# USB_USB2SS_PHY2_0F908000h register map
Vendor: Texas Instruments
Registers are 32-bit, read-write, reset 0x0 unless marked. A register's access mark holds for its fields unless they carry their own. Offsets are as the file gives them; [hi:lo] are bit positions; {n}, {i} and the like mark numbered series.

## usb2ss_phy2 (part 3 of 3)
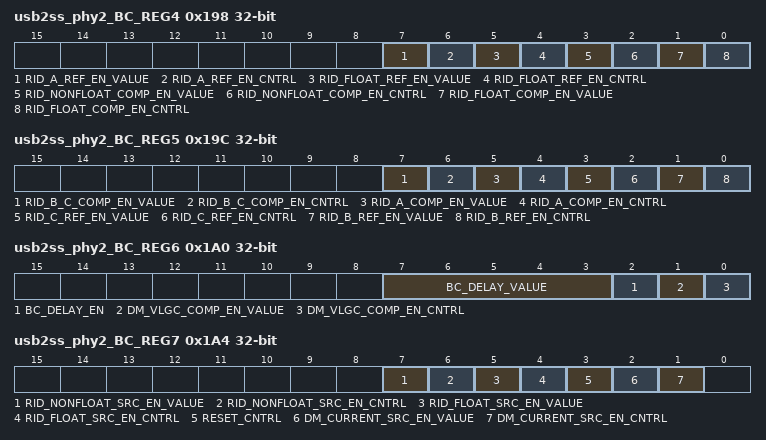
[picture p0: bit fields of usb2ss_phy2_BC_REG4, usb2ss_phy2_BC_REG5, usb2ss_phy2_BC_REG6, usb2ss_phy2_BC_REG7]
0x198 usb2ss_phy2_BC_REG4 — This is a reserved register or field. It should not be written or read, and the value should be ignored.
  [7] RID_A_REF_EN_VALUE — This is a reserved register or field. It should not be written or read, and the value should be ignored. Reset Source: usb2_sync_preset_n
  [6] RID_A_REF_EN_CNTRL — This is a reserved register or field. It should not be written or read, and the value should be ignored. Reset Source: usb2_sync_preset_n
  [5] RID_FLOAT_REF_EN_VALUE — This is a reserved register or field. It should not be written or read, and the value should be ignored. Reset Source: usb2_sync_preset_n
  [4] RID_FLOAT_REF_EN_CNTRL — This is a reserved register or field. It should not be written or read, and the value should be ignored. Reset Source: usb2_sync_preset_n
  [3] RID_NONFLOAT_COMP_EN_VALUE — This is a reserved register or field. It should not be written or read, and the value should be ignored. Reset Source: usb2_sync_preset_n
  [2] RID_NONFLOAT_COMP_EN_CNTRL — This is a reserved register or field. It should not be written or read, and the value should be ignored. Reset Source: usb2_sync_preset_n
  [1] RID_FLOAT_COMP_EN_VALUE — This is a reserved register or field. It should not be written or read, and the value should be ignored. Reset Source: usb2_sync_preset_n
  [0] RID_FLOAT_COMP_EN_CNTRL — This is a reserved register or field. It should not be written or read, and the value should be ignored. Reset Source: usb2_sync_preset_n
0x19C usb2ss_phy2_BC_REG5 — This is a reserved register or field. It should not be written or read, and the value should be ignored.
  [7] RID_B_C_COMP_EN_VALUE — This is a reserved register or field. It should not be written or read, and the value should be ignored. Reset Source: usb2_sync_preset_n
  [6] RID_B_C_COMP_EN_CNTRL — This is a reserved register or field. It should not be written or read, and the value should be ignored. Reset Source: usb2_sync_preset_n
  [5] RID_A_COMP_EN_VALUE — This is a reserved register or field. It should not be written or read, and the value should be ignored. Reset Source: usb2_sync_preset_n
  [4] RID_A_COMP_EN_CNTRL — This is a reserved register or field. It should not be written or read, and the value should be ignored. Reset Source: usb2_sync_preset_n
  [3] RID_C_REF_EN_VALUE — This is a reserved register or field. It should not be written or read, and the value should be ignored. Reset Source: usb2_sync_preset_n
  [2] RID_C_REF_EN_CNTRL — This is a reserved register or field. It should not be written or read, and the value should be ignored. Reset Source: usb2_sync_preset_n
  [1] RID_B_REF_EN_VALUE — This is a reserved register or field. It should not be written or read, and the value should be ignored. Reset Source: usb2_sync_preset_n
  [0] RID_B_REF_EN_CNTRL — This is a reserved register or field. It should not be written or read, and the value should be ignored. Reset Source: usb2_sync_preset_n
0x1A0 usb2ss_phy2_BC_REG6 — This is a reserved register or field. It should not be written or read, and the value should be ignored.
  [7:3] BC_DELAY_VALUE — This is a reserved register or field. It should not be written or read, and the value should be ignored. Reset Source: usb2_sync_preset_n
  [2] BC_DELAY_EN — This is a reserved register or field. It should not be written or read, and the value should be ignored. Reset Source: usb2_sync_preset_n
  [1] DM_VLGC_COMP_EN_VALUE — This is a reserved register or field. It should not be written or read, and the value should be ignored. Reset Source: usb2_sync_preset_n
  [0] DM_VLGC_COMP_EN_CNTRL — This is a reserved register or field. It should not be written or read, and the value should be ignored. Reset Source: usb2_sync_preset_n
0x1A4 usb2ss_phy2_BC_REG7 — This is a reserved register or field. It should not be written or read, and the value should be ignored.
  [7] RID_NONFLOAT_SRC_EN_VALUE — This is a reserved register or field. It should not be written or read, and the value should be ignored. Reset Source: usb2_sync_preset_n
  [6] RID_NONFLOAT_SRC_EN_CNTRL — This is a reserved register or field. It should not be written or read, and the value should be ignored. Reset Source: usb2_sync_preset_n
  [5] RID_FLOAT_SRC_EN_VALUE — This is a reserved register or field. It should not be written or read, and the value should be ignored. Reset Source: usb2_sync_preset_n
  [4] RID_FLOAT_SRC_EN_CNTRL — This is a reserved register or field. It should not be written or read, and the value should be ignored. Reset Source: usb2_sync_preset_n
  [3] RESET_CNTRL — This is a reserved register or field. It should not be written or read, and the value should be ignored. Reset Source: usb2_sync_preset_n
  [2] DM_CURRENT_SRC_EN_VALUE — This is a reserved register or field. It should not be written or read, and the value should be ignored. Reset Source: usb2_sync_preset_n
  [1] DM_CURRENT_SRC_EN_CNTRL — This is a reserved register or field. It should not be written or read, and the value should be ignored. Reset Source: usb2_sync_preset_n
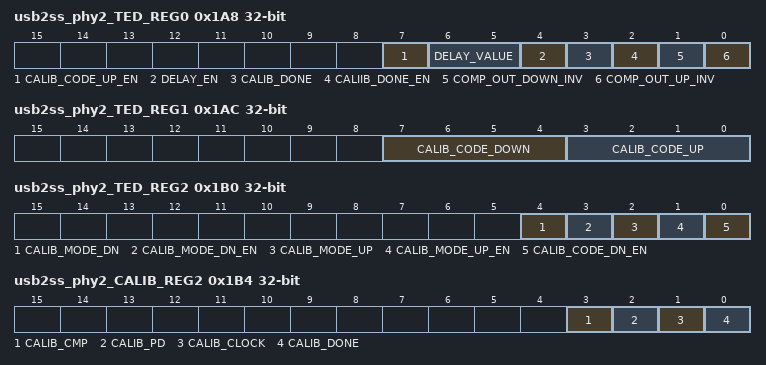
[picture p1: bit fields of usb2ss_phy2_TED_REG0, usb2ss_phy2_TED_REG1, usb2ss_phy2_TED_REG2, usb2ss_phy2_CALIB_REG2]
0x1A8 usb2ss_phy2_TED_REG0 — This is a reserved register or field. It should not be written or read, and the value should be ignored.
  [7] CALIB_CODE_UP_EN — This is a reserved register or field. It should not be written or read, and the value should be ignored. Reset Source: usb2_sync_preset_n
  [6:5] DELAY_VALUE — Delay is 8us Reset Source: usb2_sync_preset_n
  [4] DELAY_EN — This is a reserved register or field. It should not be written or read, and the value should be ignored. Reset Source: usb2_sync_preset_n
  [3] CALIB_DONE — This is a reserved register or field. It should not be written or read, and the value should be ignored. Reset Source: usb2_sync_preset_n
  [2] CALIIB_DONE_EN — This is a reserved register or field. It should not be written or read, and the value should be ignored. Reset Source: usb2_sync_preset_n
  [1] COMP_OUT_DOWN_INV — This is a reserved register or field. It should not be written or read, and the value should be ignored. Reset Source: usb2_sync_preset_n
  [0] COMP_OUT_UP_INV — This is a reserved register or field. It should not be written or read, and the value should be ignored. Reset Source: usb2_sync_preset_n
0x1AC usb2ss_phy2_TED_REG1 — This is a reserved register or field. It should not be written or read, and the value should be ignored.
  [7:4] CALIB_CODE_DOWN — This is a reserved register or field. It should not be written or read, and the value should be ignored. Reset Source: usb2_sync_preset_n
  [3:0] CALIB_CODE_UP — This is a reserved register or field. It should not be written or read, and the value should be ignored. Reset Source: usb2_sync_preset_n
0x1B0 usb2ss_phy2_TED_REG2 — This is a reserved register or field. It should not be written or read, and the value should be ignored.
  [4] CALIB_MODE_DN — This is a reserved register or field. It should not be written or read, and the value should be ignored. Reset Source: usb2_sync_preset_n
  [3] CALIB_MODE_DN_EN — This is a reserved register or field. It should not be written or read, and the value should be ignored. Reset Source: usb2_sync_preset_n
  [2] CALIB_MODE_UP — This is a reserved register or field. It should not be written or read, and the value should be ignored. Reset Source: usb2_sync_preset_n
  [1] CALIB_MODE_UP_EN — This is a reserved register or field. It should not be written or read, and the value should be ignored. Reset Source: usb2_sync_preset_n
  [0] CALIB_CODE_DN_EN — This is a reserved register or field. It should not be written or read, and the value should be ignored. Reset Source: usb2_sync_preset_n
0x1B4 usb2ss_phy2_CALIB_REG2 ro — This is a reserved register or field. It should not be written or read, and the value should be ignored.
  [3] CALIB_CMP — This is a reserved register or field. It should not be written or read, and the value should be ignored. Reset Source: usb2_sync_preset_n
  [2] CALIB_PD — This is a reserved register or field. It should not be written or read, and the value should be ignored. Reset Source: usb2_sync_preset_n
  [1] CALIB_CLOCK — This is a reserved register or field. It should not be written or read, and the value should be ignored. Reset Source: usb2_sync_preset_n
  [0] CALIB_DONE — This is a reserved register or field. It should not be written or read, and the value should be ignored. Reset Source: usb2_sync_preset_n
0x1B8 usb2ss_phy2_CALIB_REG3 ro — Resistor calibration code
  [4:0] BG_UNIT_RES_CALIB — Resistor calibration code from the calibration block Reset Source: usb2_sync_preset_n
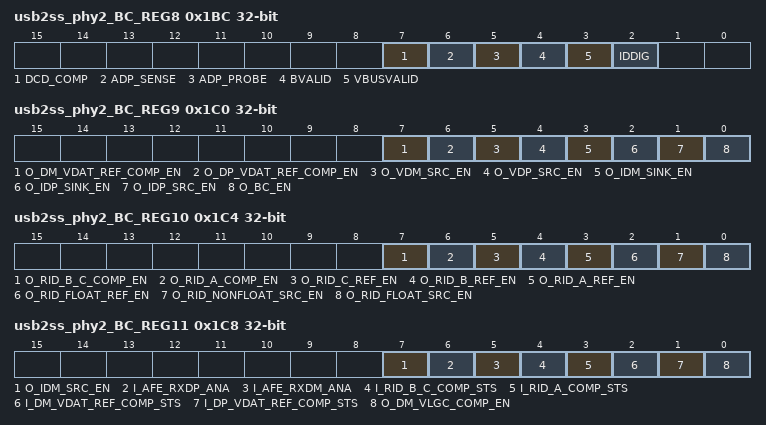
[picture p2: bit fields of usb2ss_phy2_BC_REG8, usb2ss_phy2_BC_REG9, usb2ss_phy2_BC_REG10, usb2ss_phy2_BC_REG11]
0x1BC usb2ss_phy2_BC_REG8 ro — This is a reserved register or field. It should not be written or read, and the value should be ignored.
  [7] DCD_COMP — This is a reserved register or field. It should not be written or read, and the value should be ignored. Reset Source: usb2_sync_preset_n
  [6] ADP_SENSE — This is a reserved register or field. It should not be written or read, and the value should be ignored. Reset Source: usb2_sync_preset_n
  [5] ADP_PROBE — This is a reserved register or field. It should not be written or read, and the value should be ignored. Reset Source: usb2_sync_preset_n
  [4] BVALID — This is a reserved register or field. It should not be written or read, and the value should be ignored. Reset Source: usb2_sync_preset_n
  [3] VBUSVALID — This is a reserved register or field. It should not be written or read, and the value should be ignored. Reset Source: usb2_sync_preset_n
  [2] IDDIG — This is a reserved register or field. It should not be written or read, and the value should be ignored. Reset Source: usb2_sync_preset_n
0x1C0 usb2ss_phy2_BC_REG9 ro — This is a reserved register or field. It should not be written or read, and the value should be ignored.
  [7] O_DM_VDAT_REF_COMP_EN — This is a reserved register or field. It should not be written or read, and the value should be ignored. Reset Source: usb2_sync_preset_n
  [6] O_DP_VDAT_REF_COMP_EN — This is a reserved register or field. It should not be written or read, and the value should be ignored. Reset Source: usb2_sync_preset_n
  [5] O_VDM_SRC_EN — This is a reserved register or field. It should not be written or read, and the value should be ignored. Reset Source: usb2_sync_preset_n
  [4] O_VDP_SRC_EN — This is a reserved register or field. It should not be written or read, and the value should be ignored. Reset Source: usb2_sync_preset_n
  [3] O_IDM_SINK_EN — This is a reserved register or field. It should not be written or read, and the value should be ignored. Reset Source: usb2_sync_preset_n
  [2] O_IDP_SINK_EN — This is a reserved register or field. It should not be written or read, and the value should be ignored. Reset Source: usb2_sync_preset_n
  [1] O_IDP_SRC_EN — This is a reserved register or field. It should not be written or read, and the value should be ignored. Reset Source: usb2_sync_preset_n
  [0] O_BC_EN — This is a reserved register or field. It should not be written or read, and the value should be ignored. Reset Source: usb2_sync_preset_n
0x1C4 usb2ss_phy2_BC_REG10 ro — This is a reserved register or field. It should not be written or read, and the value should be ignored.
  [7] O_RID_B_C_COMP_EN — This is a reserved register or field. It should not be written or read, and the value should be ignored. Reset Source: usb2_sync_preset_n
  [6] O_RID_A_COMP_EN — This is a reserved register or field. It should not be written or read, and the value should be ignored. Reset Source: usb2_sync_preset_n
  [5] O_RID_C_REF_EN — This is a reserved register or field. It should not be written or read, and the value should be ignored. Reset Source: usb2_sync_preset_n
  [4] O_RID_B_REF_EN — This is a reserved register or field. It should not be written or read, and the value should be ignored. Reset Source: usb2_sync_preset_n
  [3] O_RID_A_REF_EN — This is a reserved register or field. It should not be written or read, and the value should be ignored. Reset Source: usb2_sync_preset_n
  [2] O_RID_FLOAT_REF_EN — This is a reserved register or field. It should not be written or read, and the value should be ignored. Reset Source: usb2_sync_preset_n
  [1] O_RID_NONFLOAT_SRC_EN — This is a reserved register or field. It should not be written or read, and the value should be ignored. Reset Source: usb2_sync_preset_n
  [0] O_RID_FLOAT_SRC_EN — This is a reserved register or field. It should not be written or read, and the value should be ignored. Reset Source: usb2_sync_preset_n
0x1C8 usb2ss_phy2_BC_REG11 ro — This is a reserved register or field. It should not be written or read, and the value should be ignored.
  [7] O_IDM_SRC_EN — This is a reserved register or field. It should not be written or read, and the value should be ignored. Reset Source: usb2_sync_preset_n
  [6] I_AFE_RXDP_ANA — This is a reserved register or field. It should not be written or read, and the value should be ignored. Reset Source: usb2_sync_preset_n
  [5] I_AFE_RXDM_ANA — This is a reserved register or field. It should not be written or read, and the value should be ignored. Reset Source: usb2_sync_preset_n
  [4] I_RID_B_C_COMP_STS — This is a reserved register or field. It should not be written or read, and the value should be ignored. Reset Source: usb2_sync_preset_n
  [3] I_RID_A_COMP_STS — This is a reserved register or field. It should not be written or read, and the value should be ignored. Reset Source: usb2_sync_preset_n
  [2] I_DM_VDAT_REF_COMP_STS — This is a reserved register or field. It should not be written or read, and the value should be ignored. Reset Source: usb2_sync_preset_n
  [1] I_DP_VDAT_REF_COMP_STS — This is a reserved register or field. It should not be written or read, and the value should be ignored. Reset Source: usb2_sync_preset_n
  [0] O_DM_VLGC_COMP_EN — This is a reserved register or field. It should not be written or read, and the value should be ignored. Reset Source: usb2_sync_preset_n
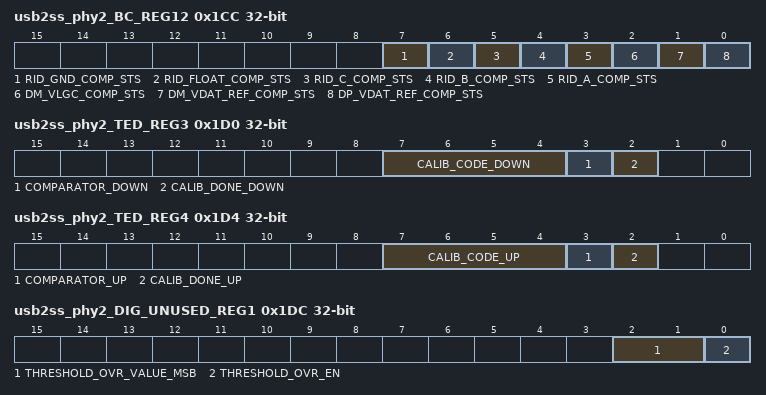
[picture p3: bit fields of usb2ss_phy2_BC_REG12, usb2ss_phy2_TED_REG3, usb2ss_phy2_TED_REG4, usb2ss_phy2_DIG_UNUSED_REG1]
0x1CC usb2ss_phy2_BC_REG12 ro — This is a reserved register or field. It should not be written or read, and the value should be ignored.
  [7] RID_GND_COMP_STS — This is a reserved register or field. It should not be written or read, and the value should be ignored. Reset Source: usb2_sync_preset_n
  [6] RID_FLOAT_COMP_STS — This is a reserved register or field. It should not be written or read, and the value should be ignored. Reset Source: usb2_sync_preset_n
  [5] RID_C_COMP_STS — This is a reserved register or field. It should not be written or read, and the value should be ignored. Reset Source: usb2_sync_preset_n
  [4] RID_B_COMP_STS — This is a reserved register or field. It should not be written or read, and the value should be ignored. Reset Source: usb2_sync_preset_n
  [3] RID_A_COMP_STS — This is a reserved register or field. It should not be written or read, and the value should be ignored. Reset Source: usb2_sync_preset_n
  [2] DM_VLGC_COMP_STS — This is a reserved register or field. It should not be written or read, and the value should be ignored. Reset Source: usb2_sync_preset_n
  [1] DM_VDAT_REF_COMP_STS — This is a reserved register or field. It should not be written or read, and the value should be ignored. Reset Source: usb2_sync_preset_n
  [0] DP_VDAT_REF_COMP_STS — This is a reserved register or field. It should not be written or read, and the value should be ignored. Reset Source: usb2_sync_preset_n
0x1D0 usb2ss_phy2_TED_REG3 ro — This is a reserved register or field. It should not be written or read, and the value should be ignored.
  [7:4] CALIB_CODE_DOWN — This is a reserved register or field. It should not be written or read, and the value should be ignored. Reset Source: usb2_sync_preset_n
  [3] COMPARATOR_DOWN — This is a reserved register or field. It should not be written or read, and the value should be ignored. Reset Source: usb2_sync_preset_n
  [2] CALIB_DONE_DOWN — This is a reserved register or field. It should not be written or read, and the value should be ignored. Reset Source: usb2_sync_preset_n
0x1D4 usb2ss_phy2_TED_REG4 ro — This is a reserved register or field. It should not be written or read, and the value should be ignored.
  [7:4] CALIB_CODE_UP — This is a reserved register or field. It should not be written or read, and the value should be ignored. Reset Source: usb2_sync_preset_n
  [3] COMPARATOR_UP — This is a reserved register or field. It should not be written or read, and the value should be ignored. Reset Source: usb2_sync_preset_n
  [2] CALIB_DONE_UP — This is a reserved register or field. It should not be written or read, and the value should be ignored. Reset Source: usb2_sync_preset_n
0x1D8 usb2ss_phy2_DIG_UNUSED_REG0 — UNUSED
  [7] GLITCH_FILTER_EN — This is a reserved register or field. It should not be written or read, and the value should be ignored. Reset Source: usb2_sync_preset_n
0x1DC usb2ss_phy2_DIG_UNUSED_REG1 — This is a reserved register or field. It should not be written or read, and the value should be ignored.
  [2:1] THRESHOLD_OVR_VALUE_MSB — This is a reserved register or field. It should not be written or read, and the value should be ignored. Reset Source: usb2_sync_preset_n
  [0] THRESHOLD_OVR_EN — This is a reserved register or field. It should not be written or read, and the value should be ignored. Reset Source: usb2_sync_preset_n
0x1E0 usb2ss_phy2_DIG_UNUSED_REG2 — This is a reserved register or field. It should not be written or read, and the value should be ignored.
  [7:0] THRESHOLD_OVR_VALUE_LSB — This is a reserved register or field. It should not be written or read, and the value should be ignored. Reset Source: usb2_sync_preset_n
0x1E4 usb2ss_phy2_DIG_UNUSED_REG3 (reset mask 0xFF) — UNUSED
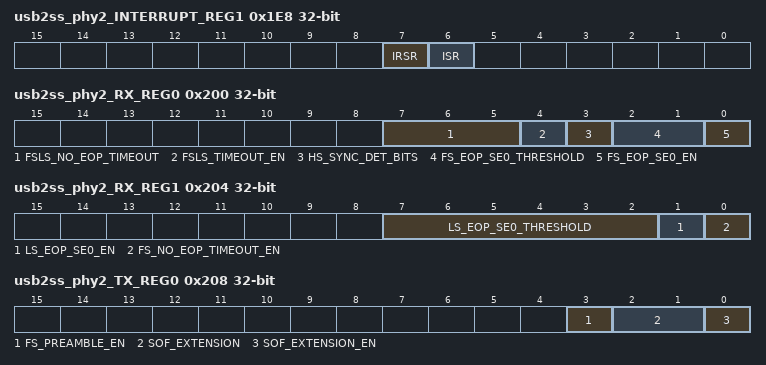
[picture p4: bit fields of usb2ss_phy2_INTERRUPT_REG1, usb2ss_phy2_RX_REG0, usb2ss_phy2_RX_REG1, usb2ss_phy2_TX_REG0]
0x1E8 usb2ss_phy2_INTERRUPT_REG1 — This is a reserved register or field. It should not be written or read, and the value should be ignored.
  [7] IRSR — This is a reserved register or field. It should not be written or read, and the value should be ignored. Reset Source: usb2_sync_preset_n
  [6] ISR — This is a reserved register or field. It should not be written or read, and the value should be ignored. Reset Source: usb2_sync_preset_n
0x1EC usb2ss_phy2_INTERRUPT_REG2 reset 0x1 — This is a reserved register or field. It should not be written or read, and the value should be ignored.
  [0] IMR — This is a reserved register or field. It should not be written or read, and the value should be ignored. Reset Source: usb2_sync_preset_n
0x200 usb2ss_phy2_RX_REG0 — This is a reserved register or field. It should not be written or read, and the value should be ignored.
  [7:5] FSLS_NO_EOP_TIMEOUT — This is a reserved register or field. It should not be written or read, and the value should be ignored. Reset Source: usb2_sync_preset_n
  [4] FSLS_TIMEOUT_EN — This is a reserved register or field. It should not be written or read, and the value should be ignored. Reset Source: usb2_sync_preset_n
  [3] HS_SYNC_DET_BITS — This is a reserved register or field. It should not be written or read, and the value should be ignored. Reset Source: usb2_sync_preset_n
  [2:1] FS_EOP_SE0_THRESHOLD — This is a reserved register or field. It should not be written or read, and the value should be ignored. Reset Source: usb2_sync_preset_n
  [0] FS_EOP_SE0_EN — This is a reserved register or field. It should not be written or read, and the value should be ignored. Reset Source: usb2_sync_preset_n
0x204 usb2ss_phy2_RX_REG1 — This is a reserved register or field. It should not be written or read, and the value should be ignored.
  [7:2] LS_EOP_SE0_THRESHOLD — This is a reserved register or field. It should not be written or read, and the value should be ignored. Reset Source: usb2_sync_preset_n
  [1] LS_EOP_SE0_EN — This is a reserved register or field. It should not be written or read, and the value should be ignored. Reset Source: usb2_sync_preset_n
  [0] FS_NO_EOP_TIMEOUT_EN — This is a reserved register or field. It should not be written or read, and the value should be ignored. Reset Source: usb2_sync_preset_n
0x208 usb2ss_phy2_TX_REG0 — This is a reserved register or field. It should not be written or read, and the value should be ignored.
  [3] FS_PREAMBLE_EN — This is a reserved register or field. It should not be written or read, and the value should be ignored. Reset Source: usb2_sync_preset_n
  [2:1] SOF_EXTENSION — This is a reserved register or field. It should not be written or read, and the value should be ignored. Reset Source: usb2_sync_preset_n
  [0] SOF_EXTENSION_EN — This is a reserved register or field. It should not be written or read, and the value should be ignored. Reset Source: usb2_sync_preset_n
0x20C usb2ss_phy2_TX_REG1 — This is a reserved register or field. It should not be written or read, and the value should be ignored.
  [7:0] PREAMBLE_VALUE — This is a reserved register or field. It should not be written or read, and the value should be ignored. Reset Source: usb2_sync_preset_n
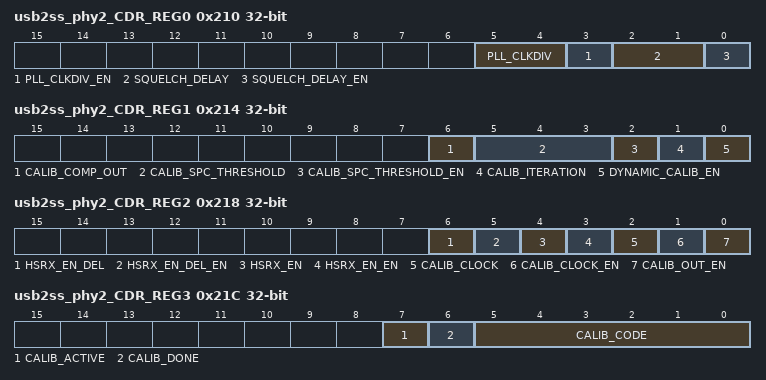
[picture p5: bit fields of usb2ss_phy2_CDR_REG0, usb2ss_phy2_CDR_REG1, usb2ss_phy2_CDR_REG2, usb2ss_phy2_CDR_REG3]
0x210 usb2ss_phy2_CDR_REG0 — This is a reserved register or field. It should not be written or read, and the value should be ignored.
  [5:4] PLL_CLKDIV — This is a reserved register or field. It should not be written or read, and the value should be ignored. Reset Source: usb2_sync_preset_n
  [3] PLL_CLKDIV_EN — This is a reserved register or field. It should not be written or read, and the value should be ignored. Reset Source: usb2_sync_preset_n
  [2:1] SQUELCH_DELAY — This is a reserved register or field. It should not be written or read, and the value should be ignored. Reset Source: usb2_sync_preset_n
  [0] SQUELCH_DELAY_EN — This is a reserved register or field. It should not be written or read, and the value should be ignored. Reset Source: usb2_sync_preset_n
0x214 usb2ss_phy2_CDR_REG1 — dynamic calib controls
  [6] CALIB_COMP_OUT — This is a reserved register or field. It should not be written or read, and the value should be ignored. Reset Source: usb2_sync_preset_n
  [5:3] CALIB_SPC_THRESHOLD — 000 The time interval between succesive calibrations is 0us, 001 The time interval between succesive calibrations is 1us, 010 The time interval between succesive calibrations is 2us, 011 The time interval between succesive calibrations is 3us, 100 The time interval between succesive calibrations is 4us, 101 The time interval between succesive calibrations is 5us, 110 The time interval between succesive calibrations is 6us, 111 The time interval between succesive calibrations is 7us. Reset Source: usb2_sync_preset_n
  [2] CALIB_SPC_THRESHOLD_EN — 0 The time interval between succesive calibrations is taken as 5us by default, 1 The time interval between succesive calibrations is taken from CDR_REG1[5:3] Reset Source: usb2_sync_preset_n
  [1] CALIB_ITERATION — This is a reserved register or field. It should not be written or read, and the value should be ignored. Reset Source: usb2_sync_preset_n
  [0] DYNAMIC_CALIB_EN — This is a reserved register or field. It should not be written or read, and the value should be ignored. Reset Source: usb2_sync_preset_n
0x218 usb2ss_phy2_CDR_REG2 — This is a reserved register or field. It should not be written or read, and the value should be ignored.
  [6] HSRX_EN_DEL — This is a reserved register or field. It should not be written or read, and the value should be ignored. Reset Source: usb2_sync_preset_n
  [5] HSRX_EN_DEL_EN — This is a reserved register or field. It should not be written or read, and the value should be ignored. Reset Source: usb2_sync_preset_n
  [4] HSRX_EN — This is a reserved register or field. It should not be written or read, and the value should be ignored. Reset Source: usb2_sync_preset_n
  [3] HSRX_EN_EN — This is a reserved register or field. It should not be written or read, and the value should be ignored. Reset Source: usb2_sync_preset_n
  [2] CALIB_CLOCK — This is a reserved register or field. It should not be written or read, and the value should be ignored. Reset Source: usb2_sync_preset_n
  [1] CALIB_CLOCK_EN — This is a reserved register or field. It should not be written or read, and the value should be ignored. Reset Source: usb2_sync_preset_n
  [0] CALIB_OUT_EN — This is a reserved register or field. It should not be written or read, and the value should be ignored. Reset Source: usb2_sync_preset_n
0x21C usb2ss_phy2_CDR_REG3 — This is a reserved register or field. It should not be written or read, and the value should be ignored.
  [7] CALIB_ACTIVE — This is a reserved register or field. It should not be written or read, and the value should be ignored. Reset Source: usb2_sync_preset_n
  [6] CALIB_DONE — This is a reserved register or field. It should not be written or read, and the value should be ignored. Reset Source: usb2_sync_preset_n
  [5:0] CALIB_CODE — This is a reserved register or field. It should not be written or read, and the value should be ignored. Reset Source: usb2_sync_preset_n
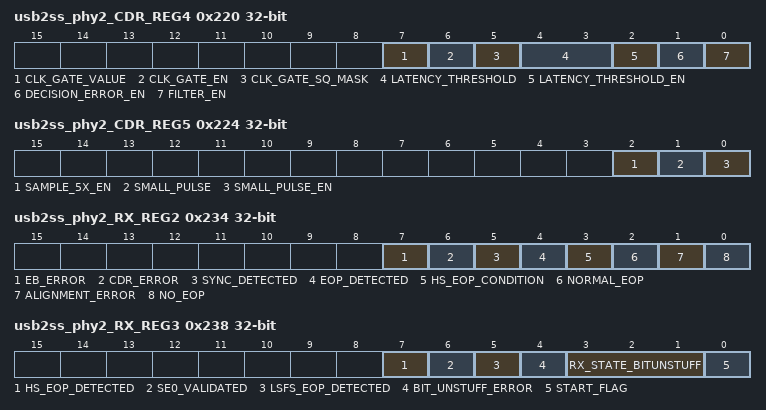
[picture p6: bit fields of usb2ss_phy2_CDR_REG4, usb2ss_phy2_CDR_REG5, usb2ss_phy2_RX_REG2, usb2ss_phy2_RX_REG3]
0x220 usb2ss_phy2_CDR_REG4 — This is a reserved register or field. It should not be written or read, and the value should be ignored.
  [7] CLK_GATE_VALUE — This is a reserved register or field. It should not be written or read, and the value should be ignored. Reset Source: usb2_sync_preset_n
  [6] CLK_GATE_EN — This is a reserved register or field. It should not be written or read, and the value should be ignored. Reset Source: usb2_sync_preset_n
  [5] CLK_GATE_SQ_MASK — This is a reserved register or field. It should not be written or read, and the value should be ignored. Reset Source: usb2_sync_preset_n
  [4:3] LATENCY_THRESHOLD — This is a reserved register or field. It should not be written or read, and the value should be ignored. Reset Source: usb2_sync_preset_n
  [2] LATENCY_THRESHOLD_EN — This is a reserved register or field. It should not be written or read, and the value should be ignored. Reset Source: usb2_sync_preset_n
  [1] DECISION_ERROR_EN — This is a reserved register or field. It should not be written or read, and the value should be ignored. Reset Source: usb2_sync_preset_n
  [0] FILTER_EN — This is a reserved register or field. It should not be written or read, and the value should be ignored. Reset Source: usb2_sync_preset_n
0x224 usb2ss_phy2_CDR_REG5 — This is a reserved register or field. It should not be written or read, and the value should be ignored.
  [2] SAMPLE_5X_EN — This is a reserved register or field. It should not be written or read, and the value should be ignored. Reset Source: usb2_sync_preset_n
  [1] SMALL_PULSE — This is a reserved register or field. It should not be written or read, and the value should be ignored. Reset Source: usb2_sync_preset_n
  [0] SMALL_PULSE_EN — This is a reserved register or field. It should not be written or read, and the value should be ignored. Reset Source: usb2_sync_preset_n
{0x210+4i} usb2ss_phy2_CDR_REG{i} (reset mask 0xFF) (i=6..8) — unused
0x234 usb2ss_phy2_RX_REG2 ro — This is a reserved register or field. It should not be written or read, and the value should be ignored.
  [7] EB_ERROR — This is a reserved register or field. It should not be written or read, and the value should be ignored. Reset Source: usb2_sync_preset_n
  [6] CDR_ERROR — This is a reserved register or field. It should not be written or read, and the value should be ignored. Reset Source: usb2_sync_preset_n
  [5] SYNC_DETECTED — This is a reserved register or field. It should not be written or read, and the value should be ignored. Reset Source: usb2_sync_preset_n
  [4] EOP_DETECTED — This is a reserved register or field. It should not be written or read, and the value should be ignored. Reset Source: usb2_sync_preset_n
  [3] HS_EOP_CONDITION — This is a reserved register or field. It should not be written or read, and the value should be ignored. Reset Source: usb2_sync_preset_n
  [2] NORMAL_EOP — This is a reserved register or field. It should not be written or read, and the value should be ignored. Reset Source: usb2_sync_preset_n
  [1] ALIGNMENT_ERROR — This is a reserved register or field. It should not be written or read, and the value should be ignored. Reset Source: usb2_sync_preset_n
  [0] NO_EOP — This is a reserved register or field. It should not be written or read, and the value should be ignored. Reset Source: usb2_sync_preset_n
0x238 usb2ss_phy2_RX_REG3 ro — This is a reserved register or field. It should not be written or read, and the value should be ignored.
  [7] HS_EOP_DETECTED — This is a reserved register or field. It should not be written or read, and the value should be ignored. Reset Source: usb2_sync_preset_n
  [6] SE0_VALIDATED — This is a reserved register or field. It should not be written or read, and the value should be ignored. Reset Source: usb2_sync_preset_n
  [5] LSFS_EOP_DETECTED — This is a reserved register or field. It should not be written or read, and the value should be ignored. Reset Source: usb2_sync_preset_n
  [4] BIT_UNSTUFF_ERROR — This is a reserved register or field. It should not be written or read, and the value should be ignored. Reset Source: usb2_sync_preset_n
  [3:1] RX_STATE_BITUNSTUFF — This is a reserved register or field. It should not be written or read, and the value should be ignored. Reset Source: usb2_sync_preset_n
  [0] START_FLAG — This is a reserved register or field. It should not be written or read, and the value should be ignored. Reset Source: usb2_sync_preset_n
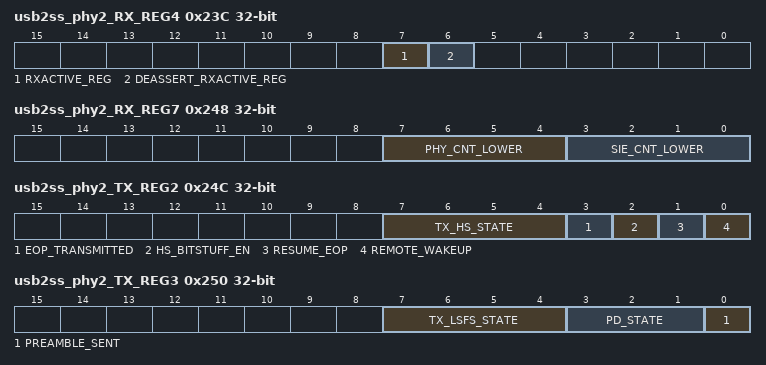
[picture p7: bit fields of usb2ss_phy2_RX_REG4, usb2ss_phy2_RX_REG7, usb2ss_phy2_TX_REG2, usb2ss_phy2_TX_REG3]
0x23C usb2ss_phy2_RX_REG4 ro — This is a reserved register or field. It should not be written or read, and the value should be ignored.
  [7] RXACTIVE_REG — This is a reserved register or field. It should not be written or read, and the value should be ignored. Reset Source: usb2_sync_preset_n
  [6] DEASSERT_RXACTIVE_REG — This is a reserved register or field. It should not be written or read, and the value should be ignored. Reset Source: usb2_sync_preset_n
0x240 usb2ss_phy2_RX_REG5 ro — This is a reserved register or field. It should not be written or read, and the value should be ignored.
  [7:0] SIE_CNT_UPPER — This is a reserved register or field. It should not be written or read, and the value should be ignored. Reset Source: usb2_sync_preset_n
0x244 usb2ss_phy2_RX_REG6 ro — This is a reserved register or field. It should not be written or read, and the value should be ignored.
  [7:0] PHY_CNT_UPPER — This is a reserved register or field. It should not be written or read, and the value should be ignored. Reset Source: usb2_sync_preset_n
0x248 usb2ss_phy2_RX_REG7 ro — This is a reserved register or field. It should not be written or read, and the value should be ignored.
  [7:4] PHY_CNT_LOWER — This is a reserved register or field. It should not be written or read, and the value should be ignored. Reset Source: usb2_sync_preset_n
  [3:0] SIE_CNT_LOWER — This is a reserved register or field. It should not be written or read, and the value should be ignored. Reset Source: usb2_sync_preset_n
0x24C usb2ss_phy2_TX_REG2 ro — This is a reserved register or field. It should not be written or read, and the value should be ignored.
  [7:4] TX_HS_STATE — This is a reserved register or field. It should not be written or read, and the value should be ignored. Reset Source: usb2_sync_preset_n
  [3] EOP_TRANSMITTED — This is a reserved register or field. It should not be written or read, and the value should be ignored. Reset Source: usb2_sync_preset_n
  [2] HS_BITSTUFF_EN — This is a reserved register or field. It should not be written or read, and the value should be ignored. Reset Source: usb2_sync_preset_n
  [1] RESUME_EOP — This is a reserved register or field. It should not be written or read, and the value should be ignored. Reset Source: usb2_sync_preset_n
  [0] REMOTE_WAKEUP — This is a reserved register or field. It should not be written or read, and the value should be ignored. Reset Source: usb2_sync_preset_n
0x250 usb2ss_phy2_TX_REG3 ro — This is a reserved register or field. It should not be written or read, and the value should be ignored.
  [7:4] TX_LSFS_STATE — This is a reserved register or field. It should not be written or read, and the value should be ignored. Reset Source: usb2_sync_preset_n
  [3:1] PD_STATE — This is a reserved register or field. It should not be written or read, and the value should be ignored. Reset Source: usb2_sync_preset_n
  [0] PREAMBLE_SENT — This is a reserved register or field. It should not be written or read, and the value should be ignored. Reset Source: usb2_sync_preset_n
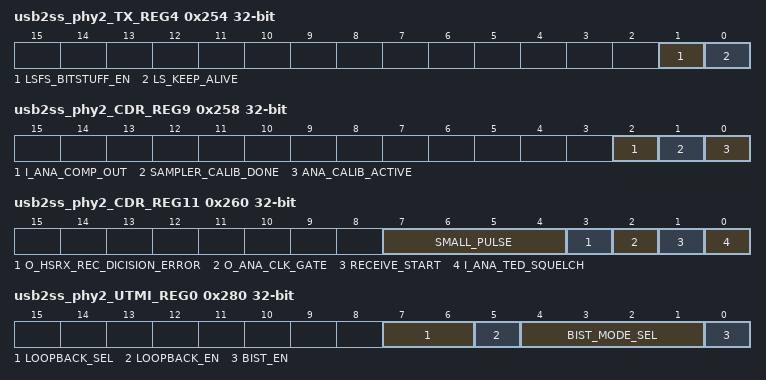
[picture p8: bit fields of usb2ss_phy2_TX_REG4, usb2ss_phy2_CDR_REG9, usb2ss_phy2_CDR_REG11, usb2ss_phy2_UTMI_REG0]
0x254 usb2ss_phy2_TX_REG4 ro — This is a reserved register or field. It should not be written or read, and the value should be ignored.
  [1] LSFS_BITSTUFF_EN — This is a reserved register or field. It should not be written or read, and the value should be ignored. Reset Source: usb2_sync_preset_n
  [0] LS_KEEP_ALIVE — This is a reserved register or field. It should not be written or read, and the value should be ignored. Reset Source: usb2_sync_preset_n
0x258 usb2ss_phy2_CDR_REG9 ro — This is a reserved register or field. It should not be written or read, and the value should be ignored.
  [2] I_ANA_COMP_OUT — This is a reserved register or field. It should not be written or read, and the value should be ignored. Reset Source: usb2_sync_preset_n
  [1] SAMPLER_CALIB_DONE — This is a reserved register or field. It should not be written or read, and the value should be ignored. Reset Source: usb2_sync_preset_n
  [0] ANA_CALIB_ACTIVE — This is a reserved register or field. It should not be written or read, and the value should be ignored. Reset Source: usb2_sync_preset_n
0x25C usb2ss_phy2_CDR_REG10 ro — This is a reserved register or field. It should not be written or read, and the value should be ignored.
  [5:0] CALIB_CODE — This is a reserved register or field. It should not be written or read, and the value should be ignored. Reset Source: usb2_sync_preset_n
0x260 usb2ss_phy2_CDR_REG11 ro — This is a reserved register or field. It should not be written or read, and the value should be ignored.
  [7:4] SMALL_PULSE — This is a reserved register or field. It should not be written or read, and the value should be ignored. Reset Source: usb2_sync_preset_n
  [3] O_HSRX_REC_DICISION_ERROR — This is a reserved register or field. It should not be written or read, and the value should be ignored. Reset Source: usb2_sync_preset_n
  [2] O_ANA_CLK_GATE — This is a reserved register or field. It should not be written or read, and the value should be ignored. Reset Source: usb2_sync_preset_n
  [1] RECEIVE_START — This is a reserved register or field. It should not be written or read, and the value should be ignored. Reset Source: usb2_sync_preset_n
  [0] I_ANA_TED_SQUELCH — This is a reserved register or field. It should not be written or read, and the value should be ignored. Reset Source: usb2_sync_preset_n
0x264 usb2ss_phy2_CDR_RE12 ro (reset mask 0xFF) — unused
{0x268+4i} usb2ss_phy2_DIG_TXRX_UNUSED_REG{i} (reset mask 0xFF) (i=0..3) — UNUSED
0x280 usb2ss_phy2_UTMI_REG0 — register UTMI_REG0
  [7:6] LOOPBACK_SEL — 00 Loopback mode selection = 00 : Reserved, 01 Loopback mode selection = 01 : LS, 10 Loopback mode selection = 10 : FS, 11 Loopback mode selection = 11 : HS Reset Source: usb2_sync_preset_n
  [5] LOOPBACK_EN — 0 Loopback mode selection is taken from primary input port-loopback[1:0], 1 Loopback mode selection is taken from UTMI_REG0[7:6]. Reset Source: usb2_sync_preset_n
  [4:1] BIST_MODE_SEL — 0 BIST for 8 bit, 1 BIST for 16 bit, 0 Error injection disabled, 1 Error injection enabled, 0 BIST for device mode, 1 BIST for host mode, 0 BIST for HS mode, 1 BIST for FS mode. Reset Source: usb2_sync_preset_n
  [0] BIST_EN — 0 BIST control signals taken from primary input BIST related ports, 1 BIST signals taken from UTMI REG0[4:1], UTMI_REG1[7:6], UTMI_REG5[7:6] Reset Source: usb2_sync_preset_n
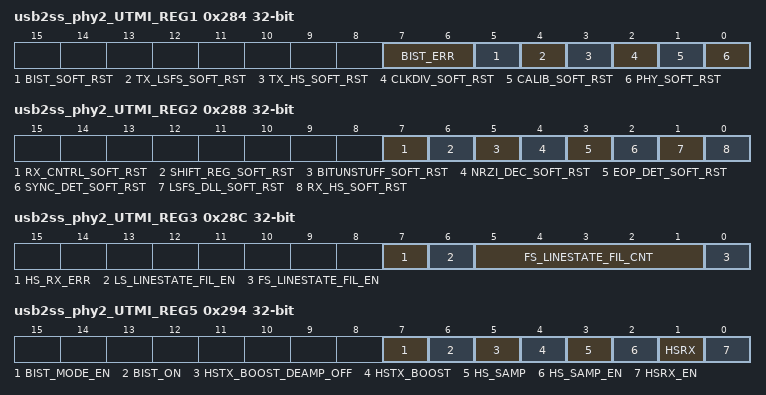
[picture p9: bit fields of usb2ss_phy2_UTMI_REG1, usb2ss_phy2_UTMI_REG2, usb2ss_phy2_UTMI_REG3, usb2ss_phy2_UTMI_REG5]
0x284 usb2ss_phy2_UTMI_REG1 — bist error injection, soft resets
  [7:6] BIST_ERR — 00 Introduce error on first packet, bist error injection = 00, 01 Introduce error on second packet,bist error injection = 01, 10 Introduce error on third packet, bist error injection = 10, 11 Introduce error on last packet, bist error injection = 11. Reset Source: usb2_sync_preset_n
  [5] BIST_SOFT_RST — This is a reserved register or field. It should not be written or read, and the value should be ignored. Reset Source: usb2_sync_preset_n
  [4] TX_LSFS_SOFT_RST — This is a reserved register or field. It should not be written or read, and the value should be ignored. Reset Source: usb2_sync_preset_n
  [3] TX_HS_SOFT_RST — This is a reserved register or field. It should not be written or read, and the value should be ignored. Reset Source: usb2_sync_preset_n
  [2] CLKDIV_SOFT_RST — This is a reserved register or field. It should not be written or read, and the value should be ignored. Reset Source: usb2_sync_preset_n
  [1] CALIB_SOFT_RST — This is a reserved register or field. It should not be written or read, and the value should be ignored. Reset Source: usb2_sync_preset_n
  [0] PHY_SOFT_RST — This is a reserved register or field. It should not be written or read, and the value should be ignored. Reset Source: usb2_sync_preset_n
0x288 usb2ss_phy2_UTMI_REG2 — This is a reserved register or field. It should not be written or read, and the value should be ignored.
  [7] RX_CNTRL_SOFT_RST — This is a reserved register or field. It should not be written or read, and the value should be ignored. Reset Source: usb2_sync_preset_n
  [6] SHIFT_REG_SOFT_RST — This is a reserved register or field. It should not be written or read, and the value should be ignored. Reset Source: usb2_sync_preset_n
  [5] BITUNSTUFF_SOFT_RST — This is a reserved register or field. It should not be written or read, and the value should be ignored. Reset Source: usb2_sync_preset_n
  [4] NRZI_DEC_SOFT_RST — This is a reserved register or field. It should not be written or read, and the value should be ignored. Reset Source: usb2_sync_preset_n
  [3] EOP_DET_SOFT_RST — This is a reserved register or field. It should not be written or read, and the value should be ignored. Reset Source: usb2_sync_preset_n
  [2] SYNC_DET_SOFT_RST — This is a reserved register or field. It should not be written or read, and the value should be ignored. Reset Source: usb2_sync_preset_n
  [1] LSFS_DLL_SOFT_RST — This is a reserved register or field. It should not be written or read, and the value should be ignored. Reset Source: usb2_sync_preset_n
  [0] RX_HS_SOFT_RST — This is a reserved register or field. It should not be written or read, and the value should be ignored. Reset Source: usb2_sync_preset_n
0x28C usb2ss_phy2_UTMI_REG3 — This is a reserved register or field. It should not be written or read, and the value should be ignored.
  [7] HS_RX_ERR — This is a reserved register or field. It should not be written or read, and the value should be ignored. Reset Source: usb2_sync_preset_n
  [6] LS_LINESTATE_FIL_EN — This is a reserved register or field. It should not be written or read, and the value should be ignored. Reset Source: usb2_sync_preset_n
  [5:1] FS_LINESTATE_FIL_CNT — This is a reserved register or field. It should not be written or read, and the value should be ignored. Reset Source: usb2_sync_preset_n
  [0] FS_LINESTATE_FIL_EN — This is a reserved register or field. It should not be written or read, and the value should be ignored. Reset Source: usb2_sync_preset_n
0x290 usb2ss_phy2_UTMI_REG4 — This is a reserved register or field. It should not be written or read, and the value should be ignored.
  [7:0] LS_LINESTATE_FIL_CNT — This is a reserved register or field. It should not be written or read, and the value should be ignored. Reset Source: usb2_sync_preset_n
0x294 usb2ss_phy2_UTMI_REG5 — BIST, hsrx data
  [7] BIST_MODE_EN — 0 BIST mode en is taken from primary input port- bist_mode_en, 1 bist_mode_en is turned on. Reset Source: usb2_sync_preset_n
  [6] BIST_ON — 0 BIST on is taken from primary input port- bist_on, 1 bist_on is enabled. Reset Source: usb2_sync_preset_n
  [5] HSTX_BOOST_DEAMP_OFF — This is a reserved register or field. It should not be written or read, and the value should be ignored. Reset Source: usb2_sync_preset_n
  [4] HSTX_BOOST — This is a reserved register or field. It should not be written or read, and the value should be ignored. Reset Source: usb2_sync_preset_n
  [3] HS_SAMP — This is a reserved register or field. It should not be written or read, and the value should be ignored. Reset Source: usb2_sync_preset_n
  [2] HS_SAMP_EN — This is a reserved register or field. It should not be written or read, and the value should be ignored. Reset Source: usb2_sync_preset_n
  [1] HSRX — This is a reserved register or field. It should not be written or read, and the value should be ignored. Reset Source: usb2_sync_preset_n
  [0] HSRX_EN — This is a reserved register or field. It should not be written or read, and the value should be ignored. Reset Source: usb2_sync_preset_n
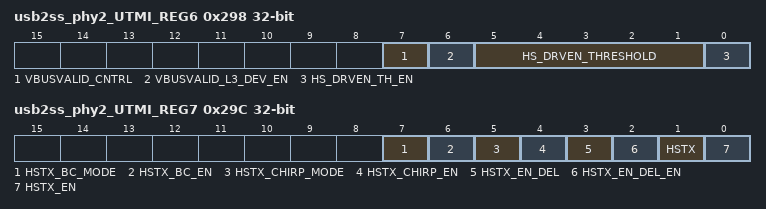
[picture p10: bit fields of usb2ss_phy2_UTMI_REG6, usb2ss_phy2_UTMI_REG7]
0x298 usb2ss_phy2_UTMI_REG6 — vbusvalid control, hs drive en threshold
  [7] VBUSVALID_CNTRL — 0 vbusvalid comparator is not enabled in L3 device Powered Off state, 1 vbusvalid comparator is enabled in L3 device Powered Off state Reset Source: usb2_sync_preset_n
  [6] VBUSVALID_L3_DEV_EN — 0 Vbusvalid comparator output comes on vbusvalid primary output port, 1 Sessvalid comparator output comes on vbusvalid primary output port. Reset Source: usb2_sync_preset_n
  [5:1] HS_DRVEN_THRESHOLD — This is a reserved register or field. It should not be written or read, and the value should be ignored. Reset Source: usb2_sync_preset_n
  [0] HS_DRVEN_TH_EN — This is a reserved register or field. It should not be written or read, and the value should be ignored. Reset Source: usb2_sync_preset_n
0x29C usb2ss_phy2_UTMI_REG7 — This is a reserved register or field. It should not be written or read, and the value should be ignored.
  [7] HSTX_BC_MODE — This is a reserved register or field. It should not be written or read, and the value should be ignored. Reset Source: usb2_sync_preset_n
  [6] HSTX_BC_EN — This is a reserved register or field. It should not be written or read, and the value should be ignored. Reset Source: usb2_sync_preset_n
  [5] HSTX_CHIRP_MODE — This is a reserved register or field. It should not be written or read, and the value should be ignored. Reset Source: usb2_sync_preset_n
  [4] HSTX_CHIRP_EN — This is a reserved register or field. It should not be written or read, and the value should be ignored. Reset Source: usb2_sync_preset_n
  [3] HSTX_EN_DEL — This is a reserved register or field. It should not be written or read, and the value should be ignored. Reset Source: usb2_sync_preset_n
  [2] HSTX_EN_DEL_EN — This is a reserved register or field. It should not be written or read, and the value should be ignored. Reset Source: usb2_sync_preset_n
  [1] HSTX — This is a reserved register or field. It should not be written or read, and the value should be ignored. Reset Source: usb2_sync_preset_n
  [0] HSTX_EN — This is a reserved register or field. It should not be written or read, and the value should be ignored. Reset Source: usb2_sync_preset_n
